VERSION ""

NS_ :

BS_:

BU_: ECU Logger

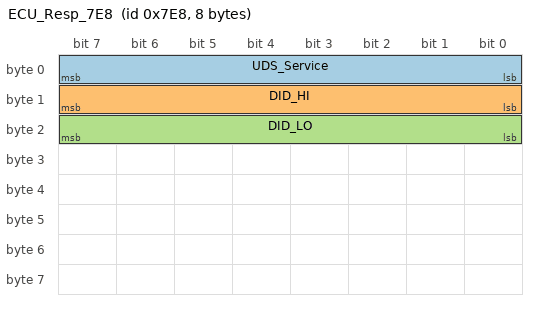
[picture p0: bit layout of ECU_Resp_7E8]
BO_ 2024 ECU_Resp_7E8: 8 ECU
 SG_ UDS_Service : 0|8@1+ (1,0) [0|255] ""  Logger
 SG_ DID_HI : 8|8@1+ (1,0) [0|255] ""  Logger
 SG_ DID_LO : 16|8@1+ (1,0) [0|255] ""  Logger
 SG_ RPM_raw multiplexor  : 24|16@1+ (1,0) [0|65535] ""  Logger
 SG_ Speed_raw multiplexor  : 24|8@1+ (1,0) [0|255] ""  Logger
 SG_ MAP_raw multiplexor  : 24|8@1+ (1,0) [0|255] ""  Logger

CM_ SG_ 2024 UDS_Service "UDS response service byte (should be 0x62)";
CM_ SG_ 2024 DID_HI "High byte of Data Identifier";
CM_ SG_ 2024 DID_LO "Low byte of Data Identifier";
CM_ SG_ 2024 RPM_raw "For DID 0x03E9: RPM = RPM_raw / 4";
CM_ SG_ 2024 Speed_raw "For DID 0x03EA: km/h = Speed_raw";
CM_ SG_ 2024 MAP_raw "For DID 0x03F0: kPa_abs = MAP_raw * 0.5";

BA_DEF_  "Protected" SG  INT 0 1;
BA_ "Protected" SG_ 2024 RPM_raw 0;
BA_ "Protected" SG_ 2024 Speed_raw 0;
BA_ "Protected" SG_ 2024 MAP_raw 0;
